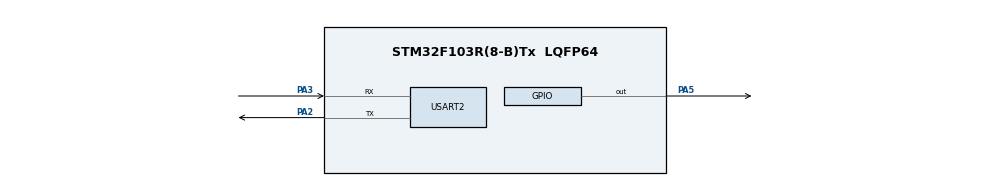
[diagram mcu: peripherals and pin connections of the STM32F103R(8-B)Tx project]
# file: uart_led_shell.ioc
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Mcu.Family=STM32F1
Mcu.Name=STM32F103R(8-B)Tx
Mcu.Package=LQFP64
NVIC.PriorityGroup=NVIC_PRIORITYGROUP_4
PA2.Mode=Asynchronous
PA2.Signal=USART2_TX
PA3.Mode=Asynchronous
PA3.Signal=USART2_RX
PA5.Signal=GPIO_Output
ProjectManager.HeapSize=0x200
ProjectManager.StackSize=0x400
ProjectManager.TargetToolchain=STM32CubeIDE
RCC.APB1Freq_Value=8000000
RCC.APB2Freq_Value=8000000
USART2.VirtualMode=VM_ASYNC
VP_SYS_VS_ND.Mode=No_Debug
board=custom

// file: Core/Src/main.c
/* USER CODE BEGIN Header */
/**
  ******************************************************************************
  * @file           : main.c
  * @brief          : Main program body
  ******************************************************************************
  * @attention
  *
  * Copyright (c) 2026 STMicroelectronics.
  * All rights reserved.
  *
  * This software is licensed under terms that can be found in the LICENSE file
  * in the root directory of this software component.
  * If no LICENSE file comes with this software, it is provided AS-IS.
  *
  ******************************************************************************
  */
/* USER CODE END Header */
#include "main.h"

/* USER CODE BEGIN Includes */
#include <string.h>
#include <ctype.h>
/* USER CODE END Includes */

UART_HandleTypeDef huart2;

void SystemClock_Config(void);
static void MX_GPIO_Init(void);
static void MX_USART2_UART_Init(void);

/* USER CODE BEGIN 0 */
uint8_t rx_char;
uint8_t rx_buf[32];
uint8_t idx = 0;
uint8_t led_state = 0;  // 0=OFF, 1=ON
/* USER CODE END 0 */

int main(void)
{

  /* MCU Configuration--------------------------------------------------------*/

  /* Reset of all peripherals, Initializes the Flash interface and the Systick. */
  HAL_Init();

  /* Configure the system clock */
  SystemClock_Config();

  /* Initialize all configured peripherals */
  MX_GPIO_Init();
  MX_USART2_UART_Init();
  /* USER CODE BEGIN 2 */
  HAL_UART_Transmit(&huart2, (uint8_t *)"UART CMD READY\r\n", 16, HAL_MAX_DELAY);
  HAL_UART_Transmit(&huart2, (uint8_t *)"Commands: ON / OFF / TOG\r\n", 27, HAL_MAX_DELAY);
  HAL_UART_Transmit(&huart2, (uint8_t *)"> ", 2, HAL_MAX_DELAY);
  /* USER CODE END 2 */

  /* Infinite loop */
  /* USER CODE BEGIN WHILE */
  while (1)
  {
      HAL_UART_Receive(&huart2, &rx_char, 1, HAL_MAX_DELAY);

      if (rx_char == '\r' || rx_char == '\n')
      {
          rx_buf[idx] = '\0';

          if (idx == 0)
          {
              continue;
          }

          for (int i = 0; i < idx; i++)
          {
              rx_buf[i] = toupper(rx_buf[i]);
          }

          if (strcmp((char *)rx_buf, "ON") == 0)
          {
              HAL_GPIO_WritePin(GPIOA, GPIO_PIN_5, GPIO_PIN_SET);
              led_state = 1;
              HAL_UART_Transmit(&huart2, (uint8_t *)"LED ON\r\n", 8, HAL_MAX_DELAY);
          }
          else if (strcmp((char *)rx_buf, "OFF") == 0)
          {
              HAL_GPIO_WritePin(GPIOA, GPIO_PIN_5, GPIO_PIN_RESET);
              led_state = 0;
              HAL_UART_Transmit(&huart2, (uint8_t *)"LED OFF\r\n", 9, HAL_MAX_DELAY);
          }
          else if (strcmp((char *)rx_buf, "TOG") == 0)
          {
              HAL_GPIO_TogglePin(GPIOA, GPIO_PIN_5);
              led_state = !led_state;
              HAL_UART_Transmit(&huart2, (uint8_t *)"LED TOGGLE\r\n", 12, HAL_MAX_DELAY);
          }
          else if (strcmp((char *)rx_buf, "HELP") == 0)
          {
              HAL_UART_Transmit(&huart2, (uint8_t *)"Commands:\r\n", 11, HAL_MAX_DELAY);
              HAL_UART_Transmit(&huart2, (uint8_t *)"ON     - turn LED on\r\n", 22, HAL_MAX_DELAY);
              HAL_UART_Transmit(&huart2, (uint8_t *)"OFF    - turn LED off\r\n", 23, HAL_MAX_DELAY);
              HAL_UART_Transmit(&huart2, (uint8_t *)"TOG    - toggle LED\r\n", 22, HAL_MAX_DELAY);
              HAL_UART_Transmit(&huart2, (uint8_t *)"STATUS - show LED state\r\n", 25, HAL_MAX_DELAY);
          }
          else if (strcmp((char *)rx_buf, "STATUS") == 0)
          {
              if (led_state)
              {
                  HAL_UART_Transmit(&huart2, (uint8_t *)"LED STATE: ON\r\n", 15, HAL_MAX_DELAY);
              }
              else
              {
                  HAL_UART_Transmit(&huart2, (uint8_t *)"LED STATE: OFF\r\n", 16, HAL_MAX_DELAY);
              }
          }
          else if (idx > 0)
          {
              HAL_UART_Transmit(&huart2, (uint8_t *)"Unknown CMD\r\n", 13, HAL_MAX_DELAY);
          }

          idx = 0;
          memset(rx_buf, 0, sizeof(rx_buf));
          HAL_UART_Transmit(&huart2, (uint8_t *)"> ", 2, HAL_MAX_DELAY);
      }
      else
      {
          if (idx < sizeof(rx_buf) - 1)
          {
              rx_buf[idx++] = rx_char;
          }
      }
  }  /* USER CODE END 3 */
}

void SystemClock_Config(void)
{
  RCC_OscInitTypeDef RCC_OscInitStruct = {0};
  RCC_ClkInitTypeDef RCC_ClkInitStruct = {0};

  /** Initializes the RCC Oscillators according to the specified parameters
  * in the RCC_OscInitTypeDef structure.
  */
  RCC_OscInitStruct.OscillatorType = RCC_OSCILLATORTYPE_HSI;
  RCC_OscInitStruct.HSIState = RCC_HSI_ON;
  RCC_OscInitStruct.HSICalibrationValue = RCC_HSICALIBRATION_DEFAULT;
  RCC_OscInitStruct.PLL.PLLState = RCC_PLL_NONE;
  if (HAL_RCC_OscConfig(&RCC_OscInitStruct) != HAL_OK)
  {
    Error_Handler();
  }

  /** Initializes the CPU, AHB and APB buses clocks
  */
  RCC_ClkInitStruct.ClockType = RCC_CLOCKTYPE_HCLK|RCC_CLOCKTYPE_SYSCLK
                              |RCC_CLOCKTYPE_PCLK1|RCC_CLOCKTYPE_PCLK2;
  RCC_ClkInitStruct.SYSCLKSource = RCC_SYSCLKSOURCE_HSI;
  RCC_ClkInitStruct.AHBCLKDivider = RCC_SYSCLK_DIV1;
  RCC_ClkInitStruct.APB1CLKDivider = RCC_HCLK_DIV1;
  RCC_ClkInitStruct.APB2CLKDivider = RCC_HCLK_DIV1;

  if (HAL_RCC_ClockConfig(&RCC_ClkInitStruct, FLASH_LATENCY_0) != HAL_OK)
  {
    Error_Handler();
  }
}

static void MX_USART2_UART_Init(void)
{

  huart2.Instance = USART2;
  huart2.Init.BaudRate = 115200;
  huart2.Init.WordLength = UART_WORDLENGTH_8B;
  huart2.Init.StopBits = UART_STOPBITS_1;
  huart2.Init.Parity = UART_PARITY_NONE;
  huart2.Init.Mode = UART_MODE_TX_RX;
  huart2.Init.HwFlowCtl = UART_HWCONTROL_NONE;
  huart2.Init.OverSampling = UART_OVERSAMPLING_16;
  if (HAL_UART_Init(&huart2) != HAL_OK)
  {
    Error_Handler();
  }

}

static void MX_GPIO_Init(void)
{
  GPIO_InitTypeDef GPIO_InitStruct = {0};

  /* GPIO Ports Clock Enable */
  __HAL_RCC_GPIOA_CLK_ENABLE();

  /*Configure GPIO pin Output Level */
  HAL_GPIO_WritePin(GPIOA, GPIO_PIN_5, GPIO_PIN_RESET);

  /*Configure GPIO pin : PA5 */
  GPIO_InitStruct.Pin = GPIO_PIN_5;
  GPIO_InitStruct.Mode = GPIO_MODE_OUTPUT_PP;
  GPIO_InitStruct.Pull = GPIO_NOPULL;
  GPIO_InitStruct.Speed = GPIO_SPEED_FREQ_LOW;
  HAL_GPIO_Init(GPIOA, &GPIO_InitStruct);

}

void Error_Handler(void)
{
  __disable_irq();
  while (1)
  {
  }
}
